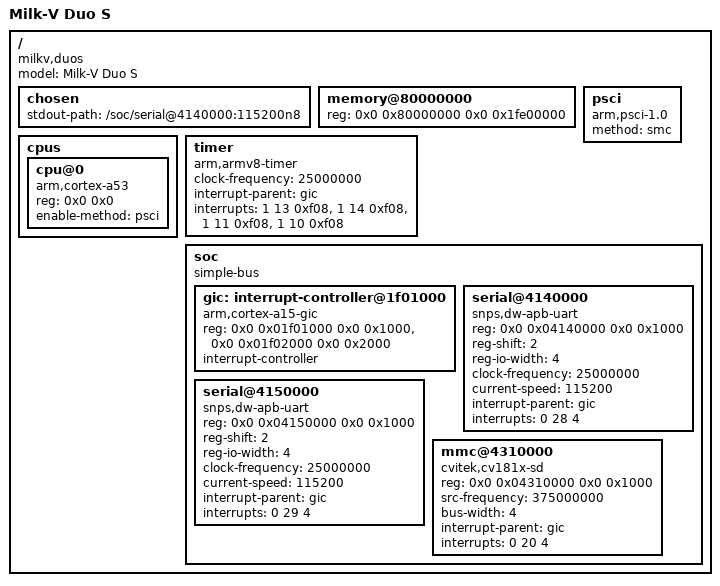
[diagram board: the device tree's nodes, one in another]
/dts-v1/;

/memreserve/ 0x80000000 0x00080000;

/ {
    compatible = "milkv,duos", "sophgo,sg2000";
    model = "Milk-V Duo S";
    #address-cells = <2>;
    #size-cells = <2>;

    chosen {
        stdout-path = "/soc/serial@4140000:115200n8";
    };

    memory@80000000 {
        device_type = "memory";
        reg = <0x0 0x80000000 0x0 0x1fe00000>;
    };

    cpus {
        #address-cells = <2>;
        #size-cells = <0>;

        cpu@0 {
            device_type = "cpu";
            compatible = "arm,cortex-a53";
            reg = <0x0 0x0>;
            enable-method = "psci";
        };
    };

    timer {
        compatible = "arm,armv8-timer";
        clock-frequency = <25000000>;
        interrupt-parent = <&gic>;
        interrupts = <1 13 0xf08>, <1 14 0xf08>, <1 11 0xf08>, <1 10 0xf08>;
    };

    psci {
        compatible = "arm,psci-1.0";
        method = "smc";
    };

    soc {
        compatible = "simple-bus";
        #address-cells = <2>;
        #size-cells = <2>;
        ranges;

        gic: interrupt-controller@1f01000 {
            compatible = "arm,cortex-a15-gic";
            reg = <0x0 0x01f01000 0x0 0x1000>,
                  <0x0 0x01f02000 0x0 0x2000>;
            interrupt-controller;
            #interrupt-cells = <3>;
        };

        serial@4140000 {
            compatible = "snps,dw-apb-uart";
            reg = <0x0 0x04140000 0x0 0x1000>;
            reg-shift = <2>;
            reg-io-width = <4>;
            clock-frequency = <25000000>;
            current-speed = <115200>;
            interrupt-parent = <&gic>;
            interrupts = <0 28 4>;
        };

        serial@4150000 {
            compatible = "snps,dw-apb-uart";
            reg = <0x0 0x04150000 0x0 0x1000>;
            reg-shift = <2>;
            reg-io-width = <4>;
            clock-frequency = <25000000>;
            current-speed = <115200>;
            interrupt-parent = <&gic>;
            interrupts = <0 29 4>;
        };

        mmc@4310000 {
            compatible = "cvitek,cv181x-sd";
            reg = <0x0 0x04310000 0x0 0x1000>;
            src-frequency = <375000000>;
            bus-width = <4>;
            interrupt-parent = <&gic>;
            interrupts = <0 20 4>;
        };
    };
};
